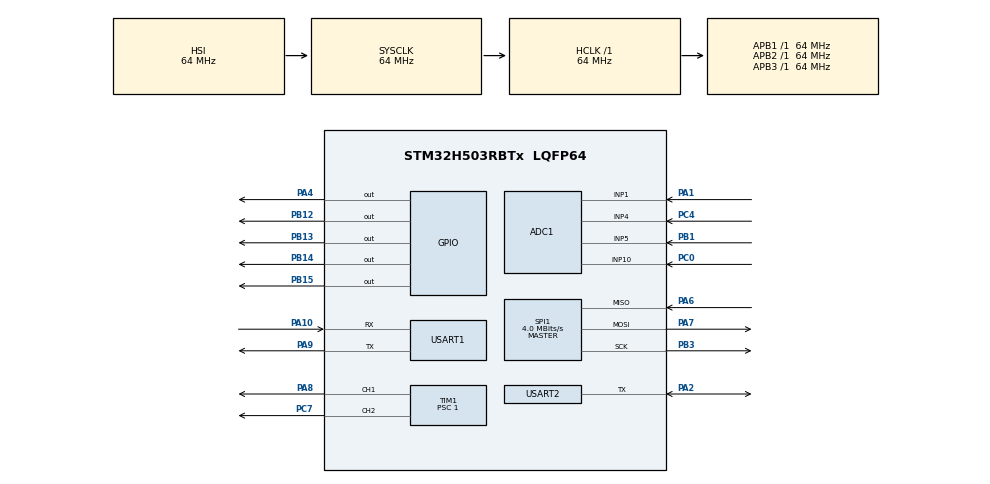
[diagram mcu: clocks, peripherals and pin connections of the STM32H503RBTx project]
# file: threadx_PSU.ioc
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ADC1.Channel-0\#ChannelRegularConversion=ADC_CHANNEL_5
ADC1.Channel-1\#ChannelRegularConversion=ADC_CHANNEL_4
ADC1.Channel-2\#ChannelRegularConversion=ADC_CHANNEL_1
ADC1.Channel-3\#ChannelRegularConversion=ADC_CHANNEL_10
ADC1.ClockPrescaler=ADC_CLOCK_ASYNC_DIV4
ADC1.ContinuousConvMode=ENABLE
ADC1.DMAContinuousRequests=ENABLE
ADC1.MonitoredBy-0\#ChannelRegularConversion=__NULL
ADC1.MonitoredBy-1\#ChannelRegularConversion=__NULL
ADC1.MonitoredBy-2\#ChannelRegularConversion=__NULL
ADC1.MonitoredBy-3\#ChannelRegularConversion=__NULL
ADC1.NbrOfConversion=4
ADC1.NbrOfConversionFlag=1
ADC1.OffsetNumber-0\#ChannelRegularConversion=ADC_OFFSET_NONE
ADC1.OffsetNumber-1\#ChannelRegularConversion=ADC_OFFSET_NONE
ADC1.OffsetNumber-2\#ChannelRegularConversion=ADC_OFFSET_NONE
ADC1.OffsetNumber-3\#ChannelRegularConversion=ADC_OFFSET_NONE
ADC1.Rank-0\#ChannelRegularConversion=1
ADC1.Rank-1\#ChannelRegularConversion=2
ADC1.Rank-2\#ChannelRegularConversion=3
ADC1.Rank-3\#ChannelRegularConversion=4
ADC1.SamplingTime-0\#ChannelRegularConversion=ADC_SAMPLETIME_92CYCLES_5
ADC1.SamplingTime-1\#ChannelRegularConversion=ADC_SAMPLETIME_47CYCLES_5
ADC1.SamplingTime-2\#ChannelRegularConversion=ADC_SAMPLETIME_92CYCLES_5
ADC1.SamplingTime-3\#ChannelRegularConversion=ADC_SAMPLETIME_47CYCLES_5
ADC1.master=1
BOOTPATH.BootPathName=LEGACY
BOOTPATH.UserSelectedBootPath=LEGACY
GPDMA1.CIRCULARMODE_GPDMACH0=ENABLE
GPDMA1.DESTDATAWIDTH_GPDMACH0=DMA_DEST_DATAWIDTH_WORD
GPDMA1.DESTINC_GPDMACH0=DMA_DINC_INCREMENTED
GPDMA1.DIRECTION_GPDMACH0=DMA_PERIPH_TO_MEMORY
GPDMA1.IPHANDLE_GPDMACH0-SIMPLEREQUEST_GPDMACH0=__NULL
GPDMA1.PRIORITY_LL_CIRCULAR_GPDMACH0=DMA_LOW_PRIORITY_HIGH_WEIGHT
GPDMA1.REQUEST_GPDMACH0=GPDMA1_REQUEST_ADC1
GPDMA1.SRCDATAWIDTH_GPDMACH0=DMA_SRC_DATAWIDTH_WORD
GPDMA1.TRANSFERALLOCATEDPORTDEST_GPDMACH0=DMA_DEST_ALLOCATED_PORT1
Mcu.Family=STM32H5
Mcu.Name=STM32H503RBTx
Mcu.Package=LQFP64
NVIC.GPDMA1_Channel0_IRQn=true\:0\:0\:false\:false\:true\:true\:false\:true\:true
NVIC.PriorityGroup=NVIC_PRIORITYGROUP_4
NVIC.TIM2_IRQn=true\:0\:0\:false\:false\:true\:false\:true\:true\:true
NVIC.USART1_IRQn=true\:0\:0\:false\:false\:true\:false\:true\:true\:true
NVIC.USART2_IRQn=true\:0\:0\:false\:false\:true\:false\:true\:true\:true
PA1.Signal=ADCx_INP1
PA10.Mode=Asynchronous
PA10.Signal=USART1_RX
PA2.Mode=Half_duplex(single_wire_mode)
PA2.Signal=USART2_TX
PA4.Signal=GPIO_Output
PA5.Signal=S_TIM2_CH1
PA6.Mode=Full_Duplex_Master
PA6.Signal=SPI1_MISO
PA7.Mode=Full_Duplex_Master
PA7.Signal=SPI1_MOSI
PA8.Signal=S_TIM1_CH1
PA9.Mode=Asynchronous
PA9.Signal=USART1_TX
PB1.Signal=ADCx_INP5
PB12.Signal=GPIO_Output
PB13.Signal=GPIO_Output
PB14.Signal=GPIO_Output
PB15.Signal=GPIO_Output
PB3(JTDO/TRACESWO).Mode=Full_Duplex_Master
PB3(JTDO/TRACESWO).Signal=SPI1_SCK
PC0.Signal=ADCx_INP10
PC4.Signal=ADCx_INP4
PC7.Signal=S_TIM1_CH2
ProjectManager.HeapSize=0x200
ProjectManager.StackSize=0x400
ProjectManager.TargetToolchain=STM32CubeIDE
RCC.ADCCLockSelection=RCC_ADCDACCLKSOURCE_PLL2R
RCC.ADCFreq_Value=32000000
RCC.AHBFreq_Value=64000000
RCC.APB1Freq_Value=64000000
RCC.APB1TimFreq_Value=64000000
RCC.APB2Freq_Value=64000000
RCC.APB2TimFreq_Value=64000000
RCC.APB3Freq_Value=64000000
RCC.CSI_VALUE=4000000
RCC.CortexFreq_Value=64000000
RCC.EPOD_VALUE=4000000
RCC.HCLKFreq_Value=64000000
RCC.HSE_VALUE=25000000
RCC.HSI48_VALUE=48000000
RCC.HSIDiv=RCC_HSI_DIV1
RCC.HSI_VALUE=64000000
RCC.LSE_VALUE=32768
RCC.LSIRC_VALUE=32000
RCC.PLL2FRACN=0
RCC.PLL2M=4
RCC.PLL2N=8
RCC.PLL2R=4
RCC.PLL2Source=RCC_PLL2_SOURCE_HSI
RCC.PLLFRACN=0
RCC.PLLN=32
RCC.SYSCLKFreq_VALUE=64000000
RCC.USBFreq_Value=48000000
RCC.VCOOutputFreq_Value=128000000
SH.ADCx_INP1.0=ADC1_INP1,IN1-Single-Ended
SH.ADCx_INP10.0=ADC1_INP10,IN10-Single-Ended
SH.ADCx_INP4.0=ADC1_INP4,IN4-Single-Ended
SH.ADCx_INP5.0=ADC1_INP5,IN5-Single-Ended
SH.S_TIM1_CH1.0=TIM1_CH1,PWM Generation1 CH1
SH.S_TIM1_CH2.0=TIM1_CH2,PWM Generation2 CH2
SH.S_TIM2_CH1.0=TIM2_CH1
SPI1.BaudRatePrescaler=SPI_BAUDRATEPRESCALER_16
SPI1.CalculateBaudRate=4.0 MBits/s
SPI1.DataSize=SPI_DATASIZE_8BIT
SPI1.Direction=SPI_DIRECTION_2LINES
SPI1.Mode=SPI_MODE_MASTER
SPI1.VirtualType=VM_MASTER
THREADX.TX_APP_GENERATE_INIT_CODE=true
THREADX.TX_TIMER_TICKS_PER_SECOND=1000
TIM1.Channel-PWM\ Generation1\ CH1=TIM_CHANNEL_1
TIM1.Channel-PWM\ Generation2\ CH2=TIM_CHANNEL_2
TIM1.PeriodNoDither=8191
TIM1.Prescaler=1
TIM2.PeriodNoDither=0xfffe-1
TIM2.Prescaler=72-1
USART1.VirtualMode-Asynchronous=VM_ASYNC
USART2.BaudRate=9600
USART2.Mode=MODE_TX_RX
USART2.VirtualMode-Half_duplex(single_wire_mode)=VM_ASYNC
VP_BOOTPATH_VS_BOOTPATH.Mode=BP_Activate
VP_CORTEX_M33_NS_VS_Hclk.Mode=Hclk_Mode
VP_GPDMA1_VS_GPDMACH0.Mode=SIMPLEREQUEST_GPDMACH0
VP_MEMORYMAP_VS_MEMORYMAP.Mode=CurAppReg
VP_PWR_VS_DBSignals.Mode=DisableDeadBatterySignals
VP_PWR_VS_LPOM.Mode=PowerOptimisation
VP_PWR_VS_SECSignals.Mode=Security/Privilege
VP_THREADX_VS_RTOSJjThreadXJjCoreJjDefault.Mode=Core_Default
VP_TIM1_VS_ClockSourceINT.Mode=Internal
VP_TIM2_VS_ClockSourceINT.Mode=Internal
board=custom

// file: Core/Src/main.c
/* USER CODE BEGIN Header */
/**
  ******************************************************************************
  * @file           : main.c
  * @brief          : Main program body
  ******************************************************************************
  * @attention
  *
  * Copyright (c) 2024 STMicroelectronics.
  * All rights reserved.
  *
  * This software is licensed under terms that can be found in the LICENSE file
  * in the root directory of this software component.
  * If no LICENSE file comes with this software, it is provided AS-IS.
  *
  ******************************************************************************
  */
/* USER CODE END Header */
#include "app_threadx.h"
#include "main.h"

/* USER CODE BEGIN Includes */
#include <stdio.h>
/* USER CODE END Includes */

ADC_HandleTypeDef hadc1;
DMA_NodeTypeDef Node_GPDMA1_Channel0;
DMA_QListTypeDef List_GPDMA1_Channel0;
DMA_HandleTypeDef handle_GPDMA1_Channel0;

SPI_HandleTypeDef hspi1;

TIM_HandleTypeDef htim1;
TIM_HandleTypeDef htim2;

UART_HandleTypeDef huart1;
UART_HandleTypeDef huart2;

void SystemClock_Config(void);
static void MX_GPIO_Init(void);
static void MX_GPDMA1_Init(void);
static void MX_USART1_UART_Init(void);
static void MX_TIM1_Init(void);
static void MX_ADC1_Init(void);
static void MX_SPI1_Init(void);
static void MX_USART2_UART_Init(void);
static void MX_TIM2_Init(void);

/* USER CODE BEGIN 0 */
const char* status1 = "Discharge";
const char* status2 = "Discharge";
uint8_t RxData2[30];

void __io_putchar(char ch) {
	HAL_UART_Transmit(&huart1, (uint8_t *)&ch, 1, 10);
}

/* USER CODE END 0 */

int main(void)
{

  /* MCU Configuration--------------------------------------------------------*/

  /* Reset of all peripherals, Initializes the Flash interface and the Systick. */
  HAL_Init();

  /* Configure the system clock */
  SystemClock_Config();

  /* Initialize all configured peripherals */
  MX_GPIO_Init();
  MX_GPDMA1_Init();
  MX_USART1_UART_Init();
  MX_TIM1_Init();
  MX_ADC1_Init();
  MX_SPI1_Init();
  MX_USART2_UART_Init();
  MX_TIM2_Init();
  /* USER CODE BEGIN 2 */
  //tx_kernel_enter();
  /* USER CODE END 2 */

  MX_ThreadX_Init();

  /* We should never get here as control is now taken by the scheduler */

  /* Infinite loop */
  while (1)
  {

  }
}

void SystemClock_Config(void)
{
  RCC_OscInitTypeDef RCC_OscInitStruct = {0};
  RCC_ClkInitTypeDef RCC_ClkInitStruct = {0};

  /** Configure the main internal regulator output voltage
  */
  __HAL_PWR_VOLTAGESCALING_CONFIG(PWR_REGULATOR_VOLTAGE_SCALE3);

  while(!__HAL_PWR_GET_FLAG(PWR_FLAG_VOSRDY)) {}

  /** Initializes the RCC Oscillators according to the specified parameters
  * in the RCC_OscInitTypeDef structure.
  */
  RCC_OscInitStruct.OscillatorType = RCC_OSCILLATORTYPE_HSI|RCC_OSCILLATORTYPE_CSI;
  RCC_OscInitStruct.HSIState = RCC_HSI_ON;
  RCC_OscInitStruct.HSIDiv = RCC_HSI_DIV1;
  RCC_OscInitStruct.HSICalibrationValue = RCC_HSICALIBRATION_DEFAULT;
  RCC_OscInitStruct.CSIState = RCC_CSI_ON;
  RCC_OscInitStruct.CSICalibrationValue = RCC_CSICALIBRATION_DEFAULT;
  RCC_OscInitStruct.PLL.PLLState = RCC_PLL_ON;
  RCC_OscInitStruct.PLL.PLLSource = RCC_PLL1_SOURCE_CSI;
  RCC_OscInitStruct.PLL.PLLM = 1;
  RCC_OscInitStruct.PLL.PLLN = 32;
  RCC_OscInitStruct.PLL.PLLP = 2;
  RCC_OscInitStruct.PLL.PLLQ = 2;
  RCC_OscInitStruct.PLL.PLLR = 2;
  RCC_OscInitStruct.PLL.PLLRGE = RCC_PLL1_VCIRANGE_2;
  RCC_OscInitStruct.PLL.PLLVCOSEL = RCC_PLL1_VCORANGE_WIDE;
  RCC_OscInitStruct.PLL.PLLFRACN = 0;
  if (HAL_RCC_OscConfig(&RCC_OscInitStruct) != HAL_OK)
  {
    Error_Handler();
  }

  /** Initializes the CPU, AHB and APB buses clocks
  */
  RCC_ClkInitStruct.ClockType = RCC_CLOCKTYPE_HCLK|RCC_CLOCKTYPE_SYSCLK
                              |RCC_CLOCKTYPE_PCLK1|RCC_CLOCKTYPE_PCLK2
                              |RCC_CLOCKTYPE_PCLK3;
  RCC_ClkInitStruct.SYSCLKSource = RCC_SYSCLKSOURCE_HSI;
  RCC_ClkInitStruct.AHBCLKDivider = RCC_SYSCLK_DIV1;
  RCC_ClkInitStruct.APB1CLKDivider = RCC_HCLK_DIV1;
  RCC_ClkInitStruct.APB2CLKDivider = RCC_HCLK_DIV1;
  RCC_ClkInitStruct.APB3CLKDivider = RCC_HCLK_DIV1;

  if (HAL_RCC_ClockConfig(&RCC_ClkInitStruct, FLASH_LATENCY_3) != HAL_OK)
  {
    Error_Handler();
  }

  /** Configure the programming delay
  */
  __HAL_FLASH_SET_PROGRAM_DELAY(FLASH_PROGRAMMING_DELAY_1);
}

static void MX_ADC1_Init(void)
{

  ADC_ChannelConfTypeDef sConfig = {0};

  /** Common config
  */
  hadc1.Instance = ADC1;
  hadc1.Init.ClockPrescaler = ADC_CLOCK_ASYNC_DIV4;
  hadc1.Init.Resolution = ADC_RESOLUTION_12B;
  hadc1.Init.DataAlign = ADC_DATAALIGN_RIGHT;
  hadc1.Init.ScanConvMode = ADC_SCAN_ENABLE;
  hadc1.Init.EOCSelection = ADC_EOC_SINGLE_CONV;
  hadc1.Init.LowPowerAutoWait = DISABLE;
  hadc1.Init.ContinuousConvMode = ENABLE;
  hadc1.Init.NbrOfConversion = 4;
  hadc1.Init.DiscontinuousConvMode = DISABLE;
  hadc1.Init.ExternalTrigConv = ADC_SOFTWARE_START;
  hadc1.Init.ExternalTrigConvEdge = ADC_EXTERNALTRIGCONVEDGE_NONE;
  hadc1.Init.DMAContinuousRequests = ENABLE;
  hadc1.Init.SamplingMode = ADC_SAMPLING_MODE_NORMAL;
  hadc1.Init.Overrun = ADC_OVR_DATA_PRESERVED;
  hadc1.Init.OversamplingMode = DISABLE;
  if (HAL_ADC_Init(&hadc1) != HAL_OK)
  {
    Error_Handler();
  }

  /** Configure Regular Channel
  */
  sConfig.Channel = ADC_CHANNEL_5;
  sConfig.Rank = ADC_REGULAR_RANK_1;
  sConfig.SamplingTime = ADC_SAMPLETIME_92CYCLES_5;
  sConfig.SingleDiff = ADC_SINGLE_ENDED;
  sConfig.OffsetNumber = ADC_OFFSET_NONE;
  sConfig.Offset = 0;
  if (HAL_ADC_ConfigChannel(&hadc1, &sConfig) != HAL_OK)
  {
    Error_Handler();
  }

  /** Configure Regular Channel
  */
  sConfig.Channel = ADC_CHANNEL_4;
  sConfig.Rank = ADC_REGULAR_RANK_2;
  sConfig.SamplingTime = ADC_SAMPLETIME_47CYCLES_5;
  if (HAL_ADC_ConfigChannel(&hadc1, &sConfig) != HAL_OK)
  {
    Error_Handler();
  }

  /** Configure Regular Channel
  */
  sConfig.Channel = ADC_CHANNEL_1;
  sConfig.Rank = ADC_REGULAR_RANK_3;
  sConfig.SamplingTime = ADC_SAMPLETIME_92CYCLES_5;
  if (HAL_ADC_ConfigChannel(&hadc1, &sConfig) != HAL_OK)
  {
    Error_Handler();
  }

  /** Configure Regular Channel
  */
  sConfig.Channel = ADC_CHANNEL_10;
  sConfig.Rank = ADC_REGULAR_RANK_4;
  sConfig.SamplingTime = ADC_SAMPLETIME_47CYCLES_5;
  if (HAL_ADC_ConfigChannel(&hadc1, &sConfig) != HAL_OK)
  {
    Error_Handler();
  }

}

static void MX_GPDMA1_Init(void)
{

  /* Peripheral clock enable */
  __HAL_RCC_GPDMA1_CLK_ENABLE();

  /* GPDMA1 interrupt Init */
    HAL_NVIC_SetPriority(GPDMA1_Channel0_IRQn, 0, 0);
    HAL_NVIC_EnableIRQ(GPDMA1_Channel0_IRQn);

}

static void MX_SPI1_Init(void)
{

  /* SPI1 parameter configuration*/
  hspi1.Instance = SPI1;
  hspi1.Init.Mode = SPI_MODE_MASTER;
  hspi1.Init.Direction = SPI_DIRECTION_2LINES;
  hspi1.Init.DataSize = SPI_DATASIZE_8BIT;
  hspi1.Init.CLKPolarity = SPI_POLARITY_LOW;
  hspi1.Init.CLKPhase = SPI_PHASE_1EDGE;
  hspi1.Init.NSS = SPI_NSS_SOFT;
  hspi1.Init.BaudRatePrescaler = SPI_BAUDRATEPRESCALER_16;
  hspi1.Init.FirstBit = SPI_FIRSTBIT_MSB;
  hspi1.Init.TIMode = SPI_TIMODE_DISABLE;
  hspi1.Init.CRCCalculation = SPI_CRCCALCULATION_DISABLE;
  hspi1.Init.CRCPolynomial = 0x7;
  hspi1.Init.NSSPMode = SPI_NSS_PULSE_ENABLE;
  hspi1.Init.NSSPolarity = SPI_NSS_POLARITY_LOW;
  hspi1.Init.FifoThreshold = SPI_FIFO_THRESHOLD_01DATA;
  hspi1.Init.MasterSSIdleness = SPI_MASTER_SS_IDLENESS_00CYCLE;
  hspi1.Init.MasterInterDataIdleness = SPI_MASTER_INTERDATA_IDLENESS_00CYCLE;
  hspi1.Init.MasterReceiverAutoSusp = SPI_MASTER_RX_AUTOSUSP_DISABLE;
  hspi1.Init.MasterKeepIOState = SPI_MASTER_KEEP_IO_STATE_DISABLE;
  hspi1.Init.IOSwap = SPI_IO_SWAP_DISABLE;
  hspi1.Init.ReadyMasterManagement = SPI_RDY_MASTER_MANAGEMENT_INTERNALLY;
  hspi1.Init.ReadyPolarity = SPI_RDY_POLARITY_HIGH;
  if (HAL_SPI_Init(&hspi1) != HAL_OK)
  {
    Error_Handler();
  }

}

static void MX_TIM1_Init(void)
{

  TIM_ClockConfigTypeDef sClockSourceConfig = {0};
  TIM_MasterConfigTypeDef sMasterConfig = {0};
  TIM_OC_InitTypeDef sConfigOC = {0};
  TIM_BreakDeadTimeConfigTypeDef sBreakDeadTimeConfig = {0};

  htim1.Instance = TIM1;
  htim1.Init.Prescaler = 1;
  htim1.Init.CounterMode = TIM_COUNTERMODE_UP;
  htim1.Init.Period = 8191;
  htim1.Init.ClockDivision = TIM_CLOCKDIVISION_DIV1;
  htim1.Init.RepetitionCounter = 0;
  htim1.Init.AutoReloadPreload = TIM_AUTORELOAD_PRELOAD_DISABLE;
  if (HAL_TIM_Base_Init(&htim1) != HAL_OK)
  {
    Error_Handler();
  }
  sClockSourceConfig.ClockSource = TIM_CLOCKSOURCE_INTERNAL;
  if (HAL_TIM_ConfigClockSource(&htim1, &sClockSourceConfig) != HAL_OK)
  {
    Error_Handler();
  }
  if (HAL_TIM_PWM_Init(&htim1) != HAL_OK)
  {
    Error_Handler();
  }
  sMasterConfig.MasterOutputTrigger = TIM_TRGO_RESET;
  sMasterConfig.MasterOutputTrigger2 = TIM_TRGO2_RESET;
  sMasterConfig.MasterSlaveMode = TIM_MASTERSLAVEMODE_DISABLE;
  if (HAL_TIMEx_MasterConfigSynchronization(&htim1, &sMasterConfig) != HAL_OK)
  {
    Error_Handler();
  }
  sConfigOC.OCMode = TIM_OCMODE_PWM1;
  sConfigOC.Pulse = 0;
  sConfigOC.OCPolarity = TIM_OCPOLARITY_HIGH;
  sConfigOC.OCNPolarity = TIM_OCNPOLARITY_HIGH;
  sConfigOC.OCFastMode = TIM_OCFAST_DISABLE;
  sConfigOC.OCIdleState = TIM_OCIDLESTATE_RESET;
  sConfigOC.OCNIdleState = TIM_OCNIDLESTATE_RESET;
  if (HAL_TIM_PWM_ConfigChannel(&htim1, &sConfigOC, TIM_CHANNEL_1) != HAL_OK)
  {
    Error_Handler();
  }
  if (HAL_TIM_PWM_ConfigChannel(&htim1, &sConfigOC, TIM_CHANNEL_2) != HAL_OK)
  {
    Error_Handler();
  }
  sBreakDeadTimeConfig.OffStateRunMode = TIM_OSSR_DISABLE;
  sBreakDeadTimeConfig.OffStateIDLEMode = TIM_OSSI_DISABLE;
  sBreakDeadTimeConfig.LockLevel = TIM_LOCKLEVEL_OFF;
  sBreakDeadTimeConfig.DeadTime = 0;
  sBreakDeadTimeConfig.BreakState = TIM_BREAK_DISABLE;
  sBreakDeadTimeConfig.BreakPolarity = TIM_BREAKPOLARITY_HIGH;
  sBreakDeadTimeConfig.BreakFilter = 0;
  sBreakDeadTimeConfig.BreakAFMode = TIM_BREAK_AFMODE_INPUT;
  sBreakDeadTimeConfig.Break2State = TIM_BREAK2_DISABLE;
  sBreakDeadTimeConfig.Break2Polarity = TIM_BREAK2POLARITY_HIGH;
  sBreakDeadTimeConfig.Break2Filter = 0;
  sBreakDeadTimeConfig.Break2AFMode = TIM_BREAK_AFMODE_INPUT;
  sBreakDeadTimeConfig.AutomaticOutput = TIM_AUTOMATICOUTPUT_DISABLE;
  if (HAL_TIMEx_ConfigBreakDeadTime(&htim1, &sBreakDeadTimeConfig) != HAL_OK)
  {
    Error_Handler();
  }
  HAL_TIM_MspPostInit(&htim1);

}

static void MX_TIM2_Init(void)
{

  TIM_ClockConfigTypeDef sClockSourceConfig = {0};
  TIM_MasterConfigTypeDef sMasterConfig = {0};

  htim2.Instance = TIM2;
  htim2.Init.Prescaler = 72-1;
  htim2.Init.CounterMode = TIM_COUNTERMODE_UP;
  htim2.Init.Period = 65533;
  htim2.Init.ClockDivision = TIM_CLOCKDIVISION_DIV1;
  htim2.Init.AutoReloadPreload = TIM_AUTORELOAD_PRELOAD_DISABLE;
  if (HAL_TIM_Base_Init(&htim2) != HAL_OK)
  {
    Error_Handler();
  }
  sClockSourceConfig.ClockSource = TIM_CLOCKSOURCE_INTERNAL;
  if (HAL_TIM_ConfigClockSource(&htim2, &sClockSourceConfig) != HAL_OK)
  {
    Error_Handler();
  }
  sMasterConfig.MasterOutputTrigger = TIM_TRGO_RESET;
  sMasterConfig.MasterSlaveMode = TIM_MASTERSLAVEMODE_DISABLE;
  if (HAL_TIMEx_MasterConfigSynchronization(&htim2, &sMasterConfig) != HAL_OK)
  {
    Error_Handler();
  }

}

static void MX_USART1_UART_Init(void)
{

  huart1.Instance = USART1;
  huart1.Init.BaudRate = 115200;
  huart1.Init.WordLength = UART_WORDLENGTH_8B;
  huart1.Init.StopBits = UART_STOPBITS_1;
  huart1.Init.Parity = UART_PARITY_NONE;
  huart1.Init.Mode = UART_MODE_TX_RX;
  huart1.Init.HwFlowCtl = UART_HWCONTROL_NONE;
  huart1.Init.OverSampling = UART_OVERSAMPLING_16;
  huart1.Init.OneBitSampling = UART_ONE_BIT_SAMPLE_DISABLE;
  huart1.Init.ClockPrescaler = UART_PRESCALER_DIV1;
  huart1.AdvancedInit.AdvFeatureInit = UART_ADVFEATURE_NO_INIT;
  if (HAL_UART_Init(&huart1) != HAL_OK)
  {
    Error_Handler();
  }
  if (HAL_UARTEx_SetTxFifoThreshold(&huart1, UART_TXFIFO_THRESHOLD_1_8) != HAL_OK)
  {
    Error_Handler();
  }
  if (HAL_UARTEx_SetRxFifoThreshold(&huart1, UART_RXFIFO_THRESHOLD_1_8) != HAL_OK)
  {
    Error_Handler();
  }
  if (HAL_UARTEx_DisableFifoMode(&huart1) != HAL_OK)
  {
    Error_Handler();
  }

}

static void MX_USART2_UART_Init(void)
{

  huart2.Instance = USART2;
  huart2.Init.BaudRate = 9600;
  huart2.Init.WordLength = UART_WORDLENGTH_8B;
  huart2.Init.StopBits = UART_STOPBITS_1;
  huart2.Init.Parity = UART_PARITY_NONE;
  huart2.Init.Mode = UART_MODE_TX_RX;
  huart2.Init.HwFlowCtl = UART_HWCONTROL_NONE;
  huart2.Init.OverSampling = UART_OVERSAMPLING_16;
  huart2.Init.OneBitSampling = UART_ONE_BIT_SAMPLE_DISABLE;
  huart2.Init.ClockPrescaler = UART_PRESCALER_DIV1;
  huart2.AdvancedInit.AdvFeatureInit = UART_ADVFEATURE_NO_INIT;
  if (HAL_HalfDuplex_Init(&huart2) != HAL_OK)
  {
    Error_Handler();
  }
  if (HAL_UARTEx_SetTxFifoThreshold(&huart2, UART_TXFIFO_THRESHOLD_1_8) != HAL_OK)
  {
    Error_Handler();
  }
  if (HAL_UARTEx_SetRxFifoThreshold(&huart2, UART_RXFIFO_THRESHOLD_1_8) != HAL_OK)
  {
    Error_Handler();
  }
  if (HAL_UARTEx_DisableFifoMode(&huart2) != HAL_OK)
  {
    Error_Handler();
  }

}

static void MX_GPIO_Init(void)
{
  GPIO_InitTypeDef GPIO_InitStruct = {0};

  /* GPIO Ports Clock Enable */
  __HAL_RCC_GPIOC_CLK_ENABLE();
  __HAL_RCC_GPIOA_CLK_ENABLE();
  __HAL_RCC_GPIOB_CLK_ENABLE();

  /*Configure GPIO pin Output Level */
  HAL_GPIO_WritePin(GPIOA, GPIO_PIN_4, GPIO_PIN_RESET);

  /*Configure GPIO pin Output Level */
  HAL_GPIO_WritePin(GPIOB, GPIO_PIN_12|GPIO_PIN_13|GPIO_PIN_14|GPIO_PIN_15, GPIO_PIN_RESET);

  /*Configure GPIO pin : PA4 */
  GPIO_InitStruct.Pin = GPIO_PIN_4;
  GPIO_InitStruct.Mode = GPIO_MODE_OUTPUT_PP;
  GPIO_InitStruct.Pull = GPIO_NOPULL;
  GPIO_InitStruct.Speed = GPIO_SPEED_FREQ_LOW;
  HAL_GPIO_Init(GPIOA, &GPIO_InitStruct);

  /*Configure GPIO pins : PB12 PB13 PB14 PB15 */
  GPIO_InitStruct.Pin = GPIO_PIN_12|GPIO_PIN_13|GPIO_PIN_14|GPIO_PIN_15;
  GPIO_InitStruct.Mode = GPIO_MODE_OUTPUT_PP;
  GPIO_InitStruct.Pull = GPIO_NOPULL;
  GPIO_InitStruct.Speed = GPIO_SPEED_FREQ_LOW;
  HAL_GPIO_Init(GPIOB, &GPIO_InitStruct);

}

/* USER CODE BEGIN 4 */
void HAL_ADC_ConvCpltCallback(ADC_HandleTypeDef* hadc) {
	if (hadc->Instance == ADC1) {
		//ReadADC_voltage_current();
	}
}

void HAL_UART_RxCpltCallback(UART_HandleTypeDef *huart) {
    if (huart->Instance == USART1) {
    }
}
/* USER CODE END 4 */

void Error_Handler(void)
{
  __disable_irq();
  while (1)
  {
  }
}
